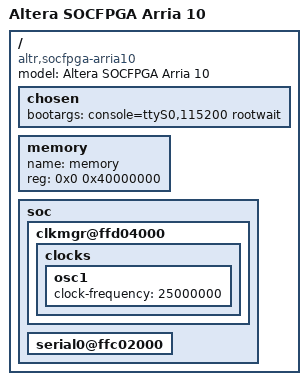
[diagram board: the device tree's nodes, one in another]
/*
 * Copyright (C) 2014 Altera Corporation <www.altera.com>
 *
 * This program is free software; you can redistribute it and/or modify
 * it under the terms of the GNU General Public License as published by
 * the Free Software Foundation; either version 2 of the License, or
 * (at your option) any later version.
 *
 * This program is distributed in the hope that it will be useful,
 * but WITHOUT ANY WARRANTY; without even the implied warranty of
 * MERCHANTABILITY or FITNESS FOR A PARTICULAR PURPOSE.  See the
 * GNU General Public License for more details.
 *
 * You should have received a copy of the GNU General Public License
 * along with this program.  If not, see <http://www.gnu.org/licenses/>.
 */

/dts-v1/;
#include "socfpga_arria10.dtsi"

/ {
	model = "Altera SOCFPGA Arria 10";
	compatible = "altr,socfpga-arria10", "altr,socfpga";

	chosen {
		bootargs = "console=ttyS0,115200 rootwait";
	};

	memory {
		name = "memory";
		device_type = "memory";
		reg = <0x0 0x40000000>; /* 1GB */
	};

	soc {
		clkmgr@ffd04000 {
			clocks {
				osc1 {
					clock-frequency = <25000000>;
				};
			};
		};

		serial0@ffc02000 {
			status = "okay";
		};
	};
};
